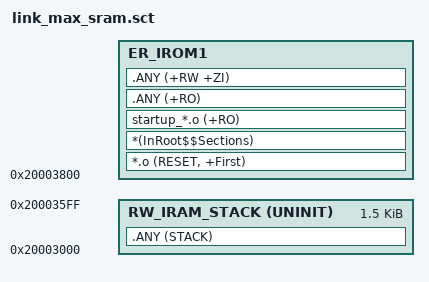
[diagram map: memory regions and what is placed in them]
LR_IROM1 0x20003800 0x7800  
{
    ER_IROM1 +0
    {
        *.o (RESET, +First)
        *(InRoot$$Sections)
        startup_*.o (+RO)
        .ANY (+RO)
        .ANY (+RW +ZI)
    }
    
    RW_IRAM_STACK 0x20003600-0x600 UNINIT 0x600
    {
        .ANY (STACK)
    }
}
